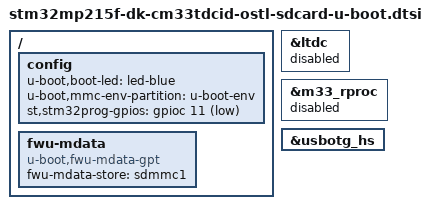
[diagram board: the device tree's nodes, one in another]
// SPDX-License-Identifier: (GPL-2.0-only OR BSD-3-Clause)
/*
 * Copyright (C) STMicroelectronics 2024 - All Rights Reserved
 */

#include "stm32mp21-u-boot.dtsi"

/ {
	config {
		u-boot,boot-led = "led-blue";
		u-boot,mmc-env-partition = "u-boot-env";
		st,stm32prog-gpios = <&gpioc 11 (GPIO_ACTIVE_LOW | GPIO_PULL_UP)>; // TOCHECK
	};

	fwu-mdata {
		compatible = "u-boot,fwu-mdata-gpt";
		fwu-mdata-store = <&sdmmc1>;
	};

	/delete-node/ typec;
};

&ltdc {
	status = "disabled";
};

&m33_rproc {
	status = "disabled";
};

&usbotg_hs {
	/delete-node/ port;
};
